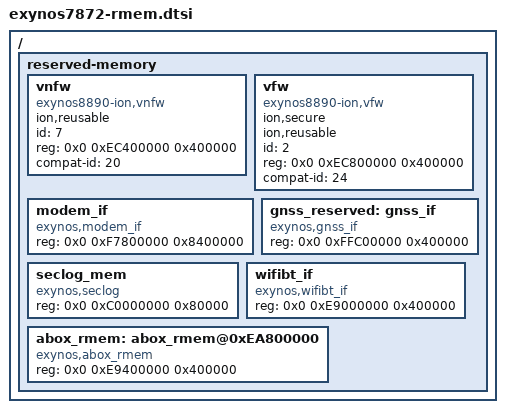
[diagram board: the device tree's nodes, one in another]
/*
 * SAMSUNG EXYNOS device tree source for reserved-memory
 *
 * Copyright (c) 2015 Samsung Electronics Co., Ltd.
 *		http://www.samsung.com
 *
 * This program is free software; you can redistribute it and/or modify
 * it under the terms of the GNU General Public License version 2 as
 * published by the Free Software Foundation.
*/

/ {
	reserved-memory {
		#address-cells = <2>;
		#size-cells = <1>;
		ranges;

		vnfw {
			compatible = "exynos8890-ion,vnfw";
			ion,reusable;
			id = <7>;
			reg = <0x0 0xEC400000 0x400000>;
			compat-id = <20>;
		};

		vfw {
			compatible = "exynos8890-ion,vfw";
			ion,secure;
			ion,reusable;
			id = <2>;
			reg = <0x0 0xEC800000 0x400000>;
			compat-id = <24>;
		};

		modem_if {
			compatible = "exynos,modem_if";
			reg = <0x0 0xF7800000 0x8400000>;
		};

		gnss_reserved: gnss_if {
			compatible = "exynos,gnss_if";
			reg = <0x0 0xFFC00000 0x400000>;
		};

		seclog_mem {
			compatible = "exynos,seclog";
			reg = <0x0 0xC0000000 0x80000>;
		};

		wifibt_if {
			compatible = "exynos,wifibt_if";
			reg = <0x0 0xE9000000 0x400000>;
		};

		abox_rmem: abox_rmem@0xEA800000 {
			compatible = "exynos,abox_rmem";
			reg = <0x0 0xE9400000 0x400000>;
		};
	};
};
